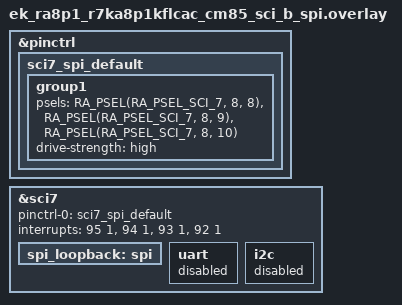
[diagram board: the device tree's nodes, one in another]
/*
 * Copyright (c) 2025 Renesas Electronics Corporation
 * SPDX-License-Identifier: Apache-2.0
 */

#define SPI_LOOPBACK_SLOW_HZ 1000000
#define SPI_LOOPBACK_FAST_HZ 2500000

&pinctrl {
	sci7_spi_default: sci7_spi_default {
		group1 {
			/* MISO MOSI SCK */
			psels = <RA_PSEL(RA_PSEL_SCI_7, 8, 8)>,
				<RA_PSEL(RA_PSEL_SCI_7, 8, 9)>,
				<RA_PSEL(RA_PSEL_SCI_7, 8, 10)>;
			drive-strength = "high";
		};
	};
};

&sci7 {
	pinctrl-0 = <&sci7_spi_default>;
	pinctrl-names = "default";
	interrupts = <95 1>, <94 1>, <93 1>, <92 1>;
	interrupt-names = "rxi", "txi", "tei", "eri";
	status = "okay";

	spi_loopback: spi {
		status = "okay";
	};

	uart {
		status = "disabled";
	};

	i2c {
		status = "disabled";
	};
};

#include "../spi-loopback.dtsi"
